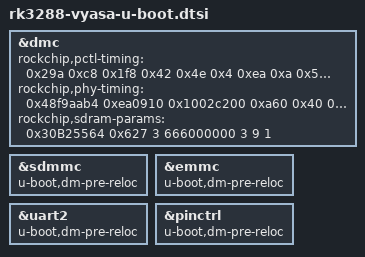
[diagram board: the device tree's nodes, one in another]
// SPDX-License-Identifier: GPL-2.0+
/*
 * Copyright (C) 2017 Jagan Teki <jagan@amarulasolutions.com>
 */

#include "rk3288-u-boot.dtsi"

&dmc {
	rockchip,pctl-timing = <0x29a 0xc8 0x1f8 0x42 0x4e 0x4 0xea 0xa
		0x5 0x0 0xa 0x7 0x19 0x24 0xa 0x7
		0x5 0xa 0x5 0x200 0x5 0x10 0x40 0x0
		0x1 0x7 0x7 0x4 0xc 0x43 0x100 0x0
		0x5 0x0>;
	rockchip,phy-timing = <0x48f9aab4 0xea0910 0x1002c200
		0xa60 0x40 0x10 0x0>;
	/* Add a dummy value to cause of-platdata think this is bytes */
	rockchip,sdram-params = <0x30B25564 0x627 3 666000000 3 9 1>;
};

&sdmmc {
	u-boot,dm-pre-reloc;
};

&emmc {
	u-boot,dm-pre-reloc;
};

&uart2 {
	u-boot,dm-pre-reloc;
};

&pinctrl {
	u-boot,dm-pre-reloc;
};
